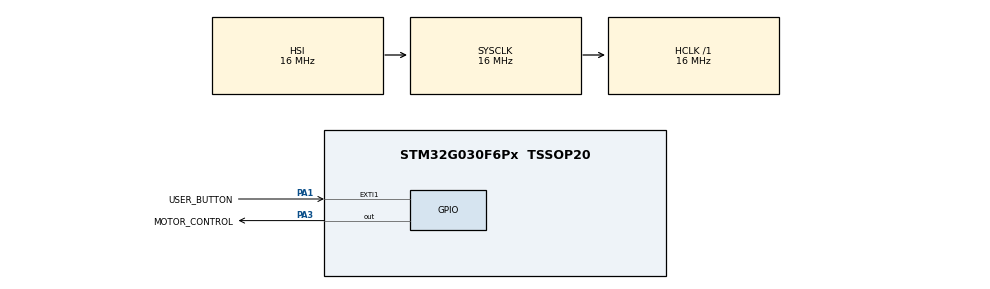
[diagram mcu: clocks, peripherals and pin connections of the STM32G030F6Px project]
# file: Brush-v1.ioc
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Mcu.Family=STM32G0
Mcu.Name=STM32G030F6Px
Mcu.Package=TSSOP20
NVIC.EXTI0_1_IRQn=true\:0\:0\:false\:false\:true\:true\:true\:true
NVIC.TIM3_IRQn=true\:0\:0\:false\:false\:true\:true\:true\:true
PA1.GPIO_Label=USER_BUTTON
PA1.GPIO_ModeDefaultEXTI=GPIO_MODE_IT_RISING
PA1.GPIO_PuPd=GPIO_NOPULL
PA1.Signal=GPXTI1
PA13.Mode=Serial_Wire
PA13.Signal=SYS_SWDIO
PA14-BOOT0.Mode=Serial_Wire
PA14-BOOT0.Signal=SYS_SWCLK
PA14-BOOT0__PA15.StandardMode=true
PA3.GPIO_Label=MOTOR_CONTROL
PA3.PinState=GPIO_PIN_RESET
PA3.Signal=GPIO_Output
PB0__PB1__PB2__PA8.StandardMode=true
PB3__PB4__PB5__PB6.StandardMode=true
PB7__PB8.StandardMode=true
PC14-OSC32_IN\ (PC14)__PB9.StandardMode=true
ProjectManager.HeapSize=0x200
ProjectManager.StackSize=0x400
ProjectManager.TargetToolchain=STM32CubeIDE
RCC.AHBFreq_Value=16000000
RCC.CortexFreq_Value=16000000
RCC.EXTERNAL_CLOCK_VALUE=12288000
RCC.HCLKFreq_Value=16000000
RCC.HSE_VALUE=8000000
RCC.HSI_VALUE=16000000
RCC.LSE_VALUE=32768
RCC.SYSCLKFreq_VALUE=16000000
RCC.VCOOutputFreq_Value=128000000
TIM3.Period=7999
TIM3.Prescaler=59999
VP_RTC_VS_RTC_Activate.Mode=RTC_Enabled
VP_TIM3_VS_ClockSourceINT.Mode=Internal
VP_TIM3_VS_OPM.Mode=OPM_bit
board=custom

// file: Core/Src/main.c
/* USER CODE BEGIN Header */
/**
  ******************************************************************************
  * @file           : main.c
  * @brief          : Main program body
  ******************************************************************************
  * @attention
  *
  * Copyright (c) 2024 STMicroelectronics.
  * All rights reserved.
  *
  * This software is licensed under terms that can be found in the LICENSE file
  * in the root directory of this software component.
  * If no LICENSE file comes with this software, it is provided AS-IS.
  *
  ******************************************************************************
  */
/* USER CODE END Header */
#include "main.h"

/* USER CODE BEGIN PTD */
volatile ButtonData bd = {0};
/* USER CODE END PTD */

RTC_HandleTypeDef hrtc;

TIM_HandleTypeDef htim3;

void SystemClock_Config(void);
static void MX_GPIO_Init(void);
static void MX_TIM3_Init(void);
static void MX_RTC_Init(void);

/* USER CODE BEGIN 0 */
uint64_t Get_Elapsed_Milliseconds(void) {
    RTC_TimeTypeDef sTime = {0};
    RTC_DateTypeDef sDate = {0};

    if (HAL_RTC_GetTime(&hrtc, &sTime, RTC_FORMAT_BIN) != HAL_OK) {
        Error_Handler();
    }

    if (HAL_RTC_GetDate(&hrtc, &sDate, RTC_FORMAT_BIN) != HAL_OK) {
        Error_Handler();
    }

    uint32_t days = sDate.Date - 1;
    uint32_t hours = days * 24 + sTime.Hours;
    uint32_t minutes = hours * 60 + sTime.Minutes;
    uint64_t seconds = minutes * 60 + sTime.Seconds;

    uint64_t milliseconds = 1000UL - ((sTime.SubSeconds * 1000UL) / (hrtc.Init.SynchPrediv + 1));
    uint64_t totalMilliseconds = (seconds * 1000UL) + milliseconds;

    return totalMilliseconds;
}

/* USER CODE END 0 */

int main(void)
{

  /* MCU Configuration--------------------------------------------------------*/

  /* Reset of all peripherals, Initializes the Flash interface and the Systick. */
  HAL_Init();

  /* Configure the system clock */
  SystemClock_Config();

  /* Initialize all configured peripherals */
  MX_GPIO_Init();
  MX_TIM3_Init();
  MX_RTC_Init();

  /* Infinite loop */
  /* USER CODE BEGIN WHILE */
  while (1)
  {
	  uint8_t status = (HAL_GPIO_ReadPin(USER_BUTTON_GPIO_Port, USER_BUTTON_Pin) == GPIO_PIN_SET);
	  if(status)
	  {
		  if (!bd.buttonPressed)
		  {
			  bd.buttonPressStartTime = HAL_GetTick();
			  bd.buttonPressed = 1;
		  }
		  else
		  {
			  if (HAL_GetTick() - bd.buttonPressStartTime >= LONG_PRESS_DURATION)
			  {
				  bd.buttonPressed = 0;
				  bd.motorStarted = 0;
				  HAL_GPIO_WritePin(MOTOR_CONTROL_GPIO_Port, MOTOR_CONTROL_Pin, GPIO_PIN_RESET);
				  bd.sleepTime = Get_Elapsed_Milliseconds();
				  bd.enterSleep = 1;
			  }
		  }
	  }
	  else
	  {
		  bd.buttonPressed = 0;
	  }

	  if(bd.motorStarted)
	  {
		  if (HAL_GetTick() - bd.motorStartTime >= MOTOR_DURATION)
		  {
			  HAL_GPIO_WritePin(MOTOR_CONTROL_GPIO_Port, MOTOR_CONTROL_Pin, GPIO_PIN_RESET);
			  bd.motorStarted = 0;
		  }
	  }

	  if(bd.enterSleep)
	  {
		  bd.enterSleep = 0;
		  HAL_SuspendTick();
		  HAL_PWR_EnterSLEEPMode(PWR_MAINREGULATOR_ON, PWR_SLEEPENTRY_WFI);
		  HAL_ResumeTick();
	  }
    /* USER CODE END WHILE */

  }
}

void SystemClock_Config(void)
{
  RCC_OscInitTypeDef RCC_OscInitStruct = {0};
  RCC_ClkInitTypeDef RCC_ClkInitStruct = {0};

  /** Configure the main internal regulator output voltage
  */
  HAL_PWREx_ControlVoltageScaling(PWR_REGULATOR_VOLTAGE_SCALE1);

  /** Initializes the RCC Oscillators according to the specified parameters
  * in the RCC_OscInitTypeDef structure.
  */
  RCC_OscInitStruct.OscillatorType = RCC_OSCILLATORTYPE_HSI|RCC_OSCILLATORTYPE_LSI;
  RCC_OscInitStruct.HSIState = RCC_HSI_ON;
  RCC_OscInitStruct.HSIDiv = RCC_HSI_DIV1;
  RCC_OscInitStruct.HSICalibrationValue = RCC_HSICALIBRATION_DEFAULT;
  RCC_OscInitStruct.LSIState = RCC_LSI_ON;
  RCC_OscInitStruct.PLL.PLLState = RCC_PLL_NONE;
  if (HAL_RCC_OscConfig(&RCC_OscInitStruct) != HAL_OK)
  {
    Error_Handler();
  }

  /** Initializes the CPU, AHB and APB buses clocks
  */
  RCC_ClkInitStruct.ClockType = RCC_CLOCKTYPE_HCLK|RCC_CLOCKTYPE_SYSCLK
                              |RCC_CLOCKTYPE_PCLK1;
  RCC_ClkInitStruct.SYSCLKSource = RCC_SYSCLKSOURCE_HSI;
  RCC_ClkInitStruct.AHBCLKDivider = RCC_SYSCLK_DIV1;
  RCC_ClkInitStruct.APB1CLKDivider = RCC_HCLK_DIV1;

  if (HAL_RCC_ClockConfig(&RCC_ClkInitStruct, FLASH_LATENCY_0) != HAL_OK)
  {
    Error_Handler();
  }
}

static void MX_RTC_Init(void)
{

  /** Initialize RTC Only
  */
  hrtc.Instance = RTC;
  hrtc.Init.HourFormat = RTC_HOURFORMAT_24;
  hrtc.Init.AsynchPrediv = 127;
  hrtc.Init.SynchPrediv = 255;
  hrtc.Init.OutPut = RTC_OUTPUT_DISABLE;
  hrtc.Init.OutPutRemap = RTC_OUTPUT_REMAP_NONE;
  hrtc.Init.OutPutPolarity = RTC_OUTPUT_POLARITY_HIGH;
  hrtc.Init.OutPutType = RTC_OUTPUT_TYPE_OPENDRAIN;
  hrtc.Init.OutPutPullUp = RTC_OUTPUT_PULLUP_NONE;
  if (HAL_RTC_Init(&hrtc) != HAL_OK)
  {
    Error_Handler();
  }
  /* USER CODE BEGIN RTC_Init 2 */
  RTC_TimeTypeDef sTime = {0};
  RTC_DateTypeDef sDate = {0};
  sTime.Hours = 0;
  sTime.Minutes = 0;
  sTime.Seconds = 0;
  sTime.SubSeconds = 0;
  sTime.TimeFormat = RTC_HOURFORMAT12_AM;
  sTime.DayLightSaving = RTC_DAYLIGHTSAVING_NONE;
  sTime.StoreOperation = RTC_STOREOPERATION_RESET;

  if (HAL_RTC_SetTime(&hrtc, &sTime, RTC_FORMAT_BIN) != HAL_OK) {
	  Error_Handler();
  }

  sDate.WeekDay = RTC_WEEKDAY_MONDAY;
  sDate.Month = RTC_MONTH_JANUARY;
  sDate.Date = 1;
  sDate.Year = 0;

  if (HAL_RTC_SetDate(&hrtc, &sDate, RTC_FORMAT_BIN) != HAL_OK) {
	  Error_Handler();
  }
  /* USER CODE END RTC_Init 2 */

}

static void MX_TIM3_Init(void)
{

  TIM_ClockConfigTypeDef sClockSourceConfig = {0};
  TIM_MasterConfigTypeDef sMasterConfig = {0};

  htim3.Instance = TIM3;
  htim3.Init.Prescaler = 59999;
  htim3.Init.CounterMode = TIM_COUNTERMODE_UP;
  htim3.Init.Period = 7999;
  htim3.Init.ClockDivision = TIM_CLOCKDIVISION_DIV1;
  htim3.Init.AutoReloadPreload = TIM_AUTORELOAD_PRELOAD_DISABLE;
  if (HAL_TIM_Base_Init(&htim3) != HAL_OK)
  {
    Error_Handler();
  }
  sClockSourceConfig.ClockSource = TIM_CLOCKSOURCE_INTERNAL;
  if (HAL_TIM_ConfigClockSource(&htim3, &sClockSourceConfig) != HAL_OK)
  {
    Error_Handler();
  }
  if (HAL_TIM_OnePulse_Init(&htim3, TIM_OPMODE_SINGLE) != HAL_OK)
  {
    Error_Handler();
  }
  sMasterConfig.MasterOutputTrigger = TIM_TRGO_RESET;
  sMasterConfig.MasterSlaveMode = TIM_MASTERSLAVEMODE_DISABLE;
  if (HAL_TIMEx_MasterConfigSynchronization(&htim3, &sMasterConfig) != HAL_OK)
  {
    Error_Handler();
  }

}

static void MX_GPIO_Init(void)
{
  GPIO_InitTypeDef GPIO_InitStruct = {0};

  /* GPIO Ports Clock Enable */
  __HAL_RCC_GPIOA_CLK_ENABLE();

  /*Configure GPIO pin Output Level */
  HAL_GPIO_WritePin(MOTOR_CONTROL_GPIO_Port, MOTOR_CONTROL_Pin, GPIO_PIN_RESET);

  /*Configure GPIO pin : USER_BUTTON_Pin */
  GPIO_InitStruct.Pin = USER_BUTTON_Pin;
  GPIO_InitStruct.Mode = GPIO_MODE_IT_RISING;
  GPIO_InitStruct.Pull = GPIO_NOPULL;
  HAL_GPIO_Init(USER_BUTTON_GPIO_Port, &GPIO_InitStruct);

  /*Configure GPIO pin : MOTOR_CONTROL_Pin */
  GPIO_InitStruct.Pin = MOTOR_CONTROL_Pin;
  GPIO_InitStruct.Mode = GPIO_MODE_OUTPUT_PP;
  GPIO_InitStruct.Pull = GPIO_NOPULL;
  GPIO_InitStruct.Speed = GPIO_SPEED_FREQ_LOW;
  HAL_GPIO_Init(MOTOR_CONTROL_GPIO_Port, &GPIO_InitStruct);

  /* EXTI interrupt init*/
  HAL_NVIC_SetPriority(EXTI0_1_IRQn, 0, 0);
  HAL_NVIC_EnableIRQ(EXTI0_1_IRQn);

}

void Error_Handler(void)
{
  __disable_irq();
  while (1)
  {
  }
}
